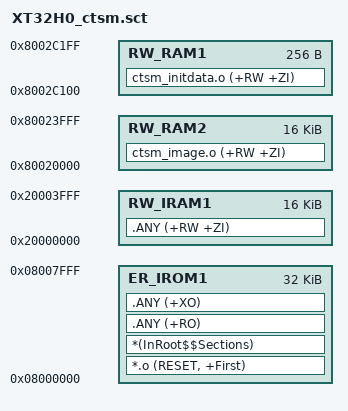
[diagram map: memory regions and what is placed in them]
; *************************************************************
; *** Scatter-Loading Description File generated by uVision ***
; *************************************************************

LR_IROM1 0x08000000 0x00008000  {    ; load region size_region
  ER_IROM1 0x08000000 0x00008000  {  ; load address = execution address
   *.o (RESET, +First)
   *(InRoot$$Sections)
   .ANY (+RO)
   .ANY (+XO)
  }
  RW_IRAM1 0x20000000 0x00004000  {  ; RW data
   .ANY (+RW +ZI)
  }
}
LR_IROM2 0x08008000 0x00008000  {    ; load region size_region
  RW_RAM2 0x80020000 0x00004000  {
   ctsm_image.o (+RW +ZI)
  }
  RW_RAM1 0x8002C100 0x00000100  {
   ctsm_initdata.o (+RW +ZI)
  }
}

